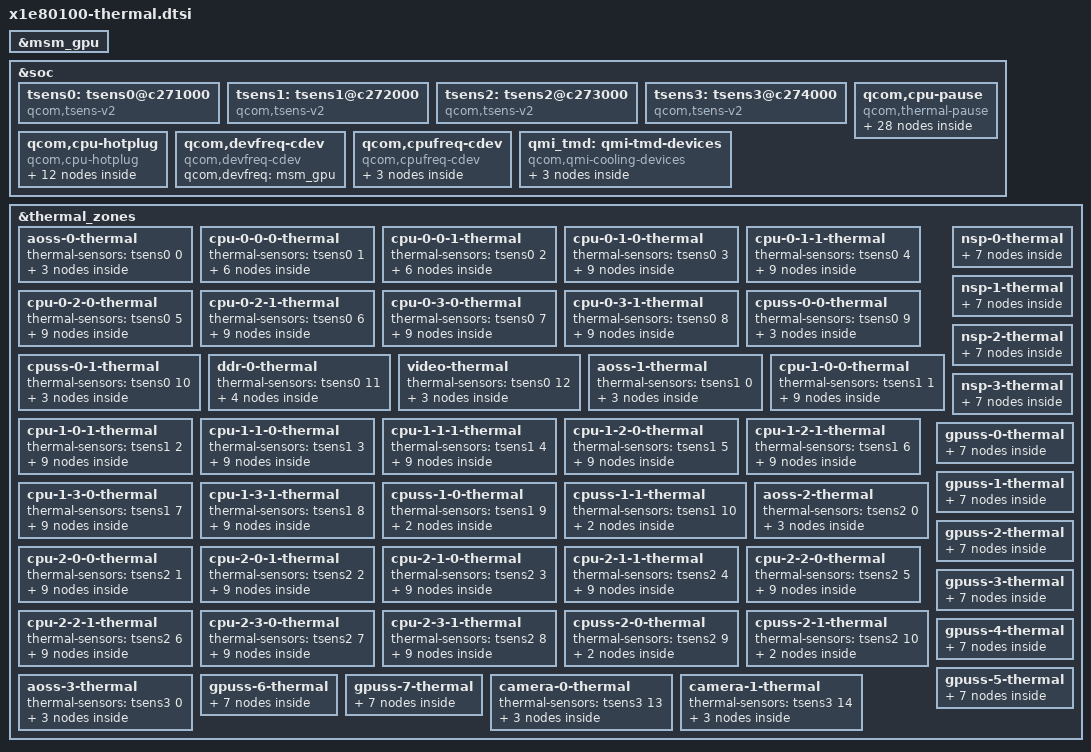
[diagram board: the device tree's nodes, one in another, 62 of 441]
// SPDX-License-Identifier: BSD-3-Clause
/*
 * Copyright (c) Qualcomm Technologies, Inc. and/or its subsidiaries.
 */

#include <dt-bindings/thermal/thermal_qti.h>

&msm_gpu {
	#cooling-cells = <2>;
};

&soc {
	tsens0: tsens0@c271000 {
		compatible = "qcom,tsens-v2";
		reg = <0x0 0xc271000 0x0 0x1ff>, /* TM */
				<0x0 0xc222000 0x0 0x1ff>; /* SROT */
		#qcom,sensors = <13>;
		interrupts = <GIC_SPI 506 IRQ_TYPE_LEVEL_HIGH>,
				<GIC_SPI 641 IRQ_TYPE_LEVEL_HIGH>;
		interrupt-names = "uplow","critical";
		#thermal-sensor-cells = <1>;
	};

	tsens1: tsens1@c272000 {
		compatible = "qcom,tsens-v2";
		reg = <0x0 0xc272000 0x0 0x1ff>, /* TM */
				<0x0 0xc223000 0x0 0x1ff>; /* SROT */
		#qcom,sensors = <11>;
		interrupts = <GIC_SPI 507 IRQ_TYPE_LEVEL_HIGH>,
				<GIC_SPI 642 IRQ_TYPE_LEVEL_HIGH>;
		interrupt-names = "uplow","critical";
		#thermal-sensor-cells = <1>;
	};

	tsens2: tsens2@c273000 {
		compatible = "qcom,tsens-v2";
		reg = <0x0 0xc273000 0x0 0x1ff>, /* TM */
				<0x0 0xc224000 0x0 0x1ff>; /* SROT */
		#qcom,sensors = <11>;
		interrupts = <GIC_SPI 508 IRQ_TYPE_LEVEL_HIGH>,
				<GIC_SPI 643 IRQ_TYPE_LEVEL_HIGH>;
		interrupt-names = "uplow","critical";
		#thermal-sensor-cells = <1>;
	};

	tsens3: tsens3@c274000 {
		compatible = "qcom,tsens-v2";
		reg = <0x0 0xc274000 0x0 0x1ff>, /* TM */
				<0x0 0xc225000 0x0 0x1ff>; /* SROT */
		#qcom,sensors = <15>;
		interrupts = <GIC_SPI 509 IRQ_TYPE_LEVEL_HIGH>,
				<GIC_SPI 770 IRQ_TYPE_LEVEL_HIGH>;
		interrupt-names = "uplow","critical";
		#thermal-sensor-cells = <1>;
	};

	qcom,cpu-pause {
		compatible = "qcom,thermal-pause";
		cpu0_pause: cpu0-pause {
			qcom,cpus = <&CPU0>;
			qcom,cdev-alias = "thermal-pause-1";
			#cooling-cells = <2>;
		};

		cpu1_pause: cpu1-pause {
			qcom,cpus = <&CPU1>;
			qcom,cdev-alias = "thermal-pause-2";
			#cooling-cells = <2>;
		};

		cpu2_pause: cpu2-pause {
			qcom,cpus = <&CPU2>;
			qcom,cdev-alias = "thermal-pause-4";
			#cooling-cells = <2>;
		};

		cpu3_pause: cpu3-pause {
			qcom,cpus = <&CPU3>;
			qcom,cdev-alias = "thermal-pause-8";
			#cooling-cells = <2>;
		};

		cpu4_pause: cpu4-pause {
			qcom,cpus = <&CPU4>;
			qcom,cdev-alias = "thermal-pause-10";
			#cooling-cells = <2>;
		};

		cpu5_pause: cpu5-pause {
			qcom,cpus = <&CPU5>;
			qcom,cdev-alias = "thermal-pause-20";
			#cooling-cells = <2>;
		};

		cpu6_pause: cpu6-pause {
			qcom,cpus = <&CPU6>;
			qcom,cdev-alias = "thermal-pause-40";
			#cooling-cells = <2>;
		};

		cpu7_pause: cpu7-pause {
			qcom,cpus = <&CPU7>;
			qcom,cdev-alias = "thermal-pause-80";
			#cooling-cells = <2>;
		};

		cpu8_pause: cpu8-pause {
			qcom,cpus = <&CPU8>;
			qcom,cdev-alias = "thermal-pause-100";
			#cooling-cells = <2>;
		};

		cpu9_pause: cpu9-pause {
			qcom,cpus = <&CPU9>;
			qcom,cdev-alias = "thermal-pause-200";
			#cooling-cells = <2>;
		};

		cpu10_pause: cpu10-pause {
			qcom,cpus = <&CPU10>;
			qcom,cdev-alias = "thermal-pause-400";
			#cooling-cells = <2>;
		};

		cpu11_pause: cpu11-pause {
			qcom,cpus = <&CPU11>;
			qcom,cdev-alias = "thermal-pause-800";
			#cooling-cells = <2>;
		};

		APC0_MX_CX_PAUSE: apc0-mx-cx-pause {
			qcom,cpus = <&CPU1 &CPU2 &CPU3>;
			qcom,cdev-alias = "thermal-pause-E";
			#cooling-cells = <2>;
		};

		APC1_MX_CX_PAUSE: apc1-mx-cx-pause {
			qcom,cpus = <&CPU4 &CPU5 &CPU6 &CPU7>;
			qcom,cdev-alias = "thermal-pause-F0";
			#cooling-cells = <2>;
		};

		APC2_MX_CX_PAUSE: apc2-mx-cx-pause {
			qcom,cpus = <&CPU8 &CPU9 &CPU10 &CPU11>;
			qcom,cdev-alias = "thermal-pause-F00";
			#cooling-cells = <2>;
		};

		APC1_APC2_MX_CX_PAUSE: apc1-apc2-mx-cx-pause {
			qcom,cpus = <&CPU4 &CPU5 &CPU6 &CPU7 &CPU8 &CPU9 &CPU10 &CPU11>;
			qcom,cdev-alias = "thermal-pause-FF0";
			#cooling-cells = <2>;
		};

		/* Thermal-engine cooling devices */
		pause-cpu0 {
			qcom,cpus = <&CPU0>;
			qcom,cdev-alias = "pause-cpu0";
		};

		pause-cpu1 {
			qcom,cpus = <&CPU1>;
			qcom,cdev-alias = "pause-cpu1";
		};

		pause-cpu2 {
			qcom,cpus = <&CPU2>;
			qcom,cdev-alias = "pause-cpu2";
		};

		pause-cpu3 {
			qcom,cpus = <&CPU3>;
			qcom,cdev-alias = "pause-cpu3";
		};

		pause-cpu4 {
			qcom,cpus = <&CPU4>;
			qcom,cdev-alias = "pause-cpu4";
		};

		pause-cpu5 {
			qcom,cpus = <&CPU5>;
			qcom,cdev-alias = "pause-cpu5";
		};

		pause-cpu6 {
			qcom,cpus = <&CPU6>;
			qcom,cdev-alias = "pause-cpu6";
		};

		pause-cpu7 {
			qcom,cpus = <&CPU7>;
			qcom,cdev-alias = "pause-cpu7";
		};

		pause-cpu8 {
			qcom,cpus = <&CPU8>;
			qcom,cdev-alias = "pause-cpu8";
		};

		pause-cpu9 {
			qcom,cpus = <&CPU9>;
			qcom,cdev-alias = "pause-cpu9";
		};

		pause-cpu10 {
			qcom,cpus = <&CPU10>;
			qcom,cdev-alias = "pause-cpu10";
		};

		pause-cpu11 {
			qcom,cpus = <&CPU11>;
			qcom,cdev-alias = "pause-cpu11";
		};
	};

	qcom,cpu-hotplug {
		compatible = "qcom,cpu-hotplug";
		cpu0_hotplug: cpu0-hotplug {
			qcom,cpu = <&CPU0>;
			qcom,cdev-alias = "cpu-hotplug0";
			#cooling-cells = <2>;
		};

		cpu1_hotplug: cpu1-hotplug {
			qcom,cpu = <&CPU1>;
			qcom,cdev-alias = "cpu-hotplug1";
			#cooling-cells = <2>;
		};

		cpu2_hotplug: cpu2-hotplug {
			qcom,cpu = <&CPU2>;
			qcom,cdev-alias = "cpu-hotplug2";
			#cooling-cells = <2>;
		};

		cpu3_hotplug: cpu3-hotplug {
			qcom,cpu = <&CPU3>;
			qcom,cdev-alias = "cpu-hotplug3";
			#cooling-cells = <2>;
		};

		cpu4_hotplug: cpu4-hotplug {
			qcom,cpu = <&CPU4>;
			qcom,cdev-alias = "cpu-hotplug4";
			#cooling-cells = <2>;
		};

		cpu5_hotplug: cpu5-hotplug {
			qcom,cpu = <&CPU5>;
			qcom,cdev-alias = "cpu-hotplug5";
			#cooling-cells = <2>;
		};

		cpu6_hotplug: cpu6-hotplug {
			qcom,cpu = <&CPU6>;
			qcom,cdev-alias = "cpu-hotplug6";
			#cooling-cells = <2>;
		};

		cpu7_hotplug: cpu7-hotplug {
			qcom,cpu = <&CPU7>;
			qcom,cdev-alias = "cpu-hotplug7";
			#cooling-cells = <2>;
		};

		cpu8_hotplug: cpu8-hotplug {
			qcom,cpu = <&CPU8>;
			qcom,cdev-alias = "cpu-hotplug8";
			#cooling-cells = <2>;
		};

		cpu9_hotplug: cpu9-hotplug {
			qcom,cpu = <&CPU9>;
			qcom,cdev-alias = "cpu-hotplug9";
			#cooling-cells = <2>;
		};

		cpu10_hotplug: cpu10-hotplug {
			qcom,cpu = <&CPU10>;
			qcom,cdev-alias = "cpu-hotplug10";
			#cooling-cells = <2>;
		};

		cpu11_hotplug: cpu11-hotplug {
			qcom,cpu = <&CPU11>;
			qcom,cdev-alias = "cpu-hotplug11";
			#cooling-cells = <2>;
		};
	};

	qcom,devfreq-cdev {
		compatible = "qcom,devfreq-cdev";
		qcom,devfreq = <&msm_gpu>;
	};

	qcom,cpufreq-cdev {
		compatible = "qcom,cpufreq-cdev";
		cpu-cluster0 {
			qcom,cpus = <&CPU0 &CPU1 &CPU2 &CPU3>;
		};

		cpu-cluster1 {
			qcom,cpus = <&CPU4 &CPU5 &CPU6 &CPU7>;
		};

		cpu-cluster2 {
			qcom,cpus = <&CPU8 &CPU9 &CPU10 &CPU11>;
		};
	};

	qmi_tmd: qmi-tmd-devices {
		compatible = "qcom,qmi-cooling-devices";
		cdsp {
			qcom,instance-id = <QMI_CDSP_INST_ID>;
			cdsp_sw: cdsp {
				qcom,qmi-dev-name = "cdsp_sw";
				#cooling-cells = <2>;
			};

			cdsp_hw: cdsp_hw {
				qcom,qmi-dev-name = "cdsp_hw";
				#cooling-cells = <2>;
			};
		};
	};
};

&thermal_zones {
	aoss-0-thermal {
		thermal-sensors = <&tsens0 0>;
		trips {
			thermal-engine-config {
				temperature = <135000>;
				hysteresis = <5000>;
				type = "passive";
			};

			reset-mon-cfg {
				temperature = <115000>;
				hysteresis = <0>;
				type = "hot";
			};
		};
	};

	cpu-0-0-0-thermal {
		thermal-sensors = <&tsens0 1>;
		trips {
			thermal-engine-config {
				temperature = <135000>;
				hysteresis = <5000>;
				type = "passive";
			};

			thermal-hal-config {
				temperature = <95000>;
				hysteresis = <5000>;
				type = "passive";
			};

			cpu0_emerg0: cpu0-emerg0-cfg {
				temperature = <108000>;
				hysteresis = <8000>;
				type = "passive";
			};

			cpu0_emerg0_1: cpu0-emerg0-1-cfg {
				temperature = <110000>;
				hysteresis = <10000>;
				type = "passive";
			};

			reset-mon-cfg {
				temperature = <115000>;
				hysteresis = <0>;
				type = "hot";
			};
		};
	};

	cpu-0-0-1-thermal {
		thermal-sensors = <&tsens0 2>;
		trips {
			thermal-engine-config {
				temperature = <135000>;
				hysteresis = <5000>;
				type = "passive";
			};

			thermal-hal-config {
				temperature = <95000>;
				hysteresis = <5000>;
				type = "passive";
			};

			cpu0_emerg1: cpu0-emerg1-cfg {
				temperature = <108000>;
				hysteresis = <8000>;
				type = "passive";
			};

			cpu0_emerg1_1: cpu0-emerg1-1-cfg {
				temperature = <110000>;
				hysteresis = <10000>;
				type = "passive";
			};

			reset-mon-cfg {
				temperature = <115000>;
				hysteresis = <0>;
				type = "hot";
			};
		};
	};

	cpu-0-1-0-thermal {
		thermal-sensors = <&tsens0 3>;
		trips {
			thermal-engine-config {
				temperature = <135000>;
				hysteresis = <5000>;
				type = "passive";
			};

			thermal-hal-config {
				temperature = <95000>;
				hysteresis = <5000>;
				type = "passive";
			};

			cpu1_emerg0: cpu1-emerg0-cfg {
				temperature = <108000>;
				hysteresis = <8000>;
				type = "passive";
			};

			cpu1_emerg0_1: cpu1-emerg0-1-cfg {
				temperature = <110000>;
				hysteresis = <10000>;
				type = "passive";
			};

			reset-mon-cfg {
				temperature = <115000>;
				hysteresis = <0>;
				type = "hot";
			};
		};

		cooling-maps {
			cpu010_cdev {
				trip = <&cpu1_emerg0>;
				cooling-device = <&cpu1_pause 1 1>;
			};

			cpu010_cdev1 {
				trip = <&cpu1_emerg0_1>;
				cooling-device = <&cpu1_hotplug 1 1>;
			};
		};
	};

	cpu-0-1-1-thermal {
		thermal-sensors = <&tsens0 4>;
		trips {
			thermal-engine-config {
				temperature = <135000>;
				hysteresis = <5000>;
				type = "passive";
			};

			thermal-hal-config {
				temperature = <95000>;
				hysteresis = <5000>;
				type = "passive";
			};

			cpu1_emerg1: cpu1-emerg1-cfg {
				temperature = <108000>;
				hysteresis = <8000>;
				type = "passive";
			};

			cpu1_emerg1_1: cpu1-emerg1-1-cfg {
				temperature = <110000>;
				hysteresis = <10000>;
				type = "passive";
			};

			reset-mon-cfg {
				temperature = <115000>;
				hysteresis = <0>;
				type = "hot";
			};
		};

		cooling-maps {
			cpu011_cdev {
				trip = <&cpu1_emerg1>;
				cooling-device = <&cpu1_pause 1 1>;
			};

			cpu011_cdev1 {
				trip = <&cpu1_emerg1_1>;
				cooling-device = <&cpu1_hotplug 1 1>;
			};
		};
	};

	cpu-0-2-0-thermal {
		thermal-sensors = <&tsens0 5>;
		trips {
			thermal-engine-config {
				temperature = <135000>;
				hysteresis = <5000>;
				type = "passive";
			};

			thermal-hal-config {
				temperature = <95000>;
				hysteresis = <5000>;
				type = "passive";
			};

			cpu2_emerg0: cpu2-emerg0-cfg {
				temperature = <108000>;
				hysteresis = <8000>;
				type = "passive";
			};

			cpu2_emerg0_1: cpu2-emerg0-1-cfg {
				temperature = <110000>;
				hysteresis = <10000>;
				type = "passive";
			};

			reset-mon-cfg {
				temperature = <115000>;
				hysteresis = <0>;
				type = "hot";
			};
		};

		cooling-maps {
			cpu020_cdev {
				trip = <&cpu2_emerg0>;
				cooling-device = <&cpu2_pause 1 1>;
			};

			cpu020_cdev1 {
				trip = <&cpu2_emerg0_1>;
				cooling-device = <&cpu2_hotplug 1 1>;
			};
		};
	};

	cpu-0-2-1-thermal {
		thermal-sensors = <&tsens0 6>;
		trips {
			thermal-engine-config {
				temperature = <135000>;
				hysteresis = <5000>;
				type = "passive";
			};

			thermal-hal-config {
				temperature = <95000>;
				hysteresis = <5000>;
				type = "passive";
			};

			cpu2_emerg1: cpu2-emerg1-cfg {
				temperature = <108000>;
				hysteresis = <8000>;
				type = "passive";
			};

			cpu2_emerg1_1: cpu2-emerg1-1-cfg {
				temperature = <110000>;
				hysteresis = <10000>;
				type = "passive";
			};

			reset-mon-cfg {
				temperature = <115000>;
				hysteresis = <0>;
				type = "hot";
			};
		};

		cooling-maps {
			cpu021_cdev {
				trip = <&cpu2_emerg1>;
				cooling-device = <&cpu2_pause 1 1>;
			};

			cpu021_cdev1 {
				trip = <&cpu2_emerg1_1>;
				cooling-device = <&cpu2_hotplug 1 1>;
			};
		};
	};

	cpu-0-3-0-thermal {
		thermal-sensors = <&tsens0 7>;
		trips {
			thermal-engine-config {
				temperature = <135000>;
				hysteresis = <5000>;
				type = "passive";
			};

			thermal-hal-config {
				temperature = <95000>;
				hysteresis = <5000>;
				type = "passive";
			};

			cpu3_emerg0: cpu3-emerg0-cfg {
				temperature = <108000>;
				hysteresis = <8000>;
				type = "passive";
			};

			cpu3_emerg0_1: cpu3-emerg0-1-cfg {
				temperature = <110000>;
				hysteresis = <10000>;
				type = "passive";
			};

			reset-mon-cfg {
				temperature = <115000>;
				hysteresis = <0>;
				type = "hot";
			};
		};

		cooling-maps {
			cpu030_cdev {
				trip = <&cpu3_emerg0>;
				cooling-device = <&cpu3_pause 1 1>;
			};

			cpu030_cdev1 {
				trip = <&cpu3_emerg0_1>;
				cooling-device = <&cpu3_hotplug 1 1>;
			};
		};
	};

	cpu-0-3-1-thermal {
		thermal-sensors = <&tsens0 8>;
		trips {
			thermal-engine-config {
				temperature = <135000>;
				hysteresis = <5000>;
				type = "passive";
			};

			thermal-hal-config {
				temperature = <95000>;
				hysteresis = <5000>;
				type = "passive";
			};

			cpu3_emerg1: cpu3-emerg1-cfg {
				temperature = <108000>;
				hysteresis = <8000>;
				type = "passive";
			};

			cpu3_emerg1_1: cpu3-emerg1-1-cfg {
				temperature = <110000>;
				hysteresis = <10000>;
				type = "passive";
			};

			reset-mon-cfg {
				temperature = <115000>;
				hysteresis = <0>;
				type = "hot";
			};
		};

		cooling-maps {
			cpu031_cdev {
				trip = <&cpu3_emerg1>;
				cooling-device = <&cpu3_pause 1 1>;
			};

			cpu031_cdev1 {
				trip = <&cpu3_emerg1_1>;
				cooling-device = <&cpu3_hotplug 1 1>;
			};
		};
	};

	cpuss-0-0-thermal {
		thermal-sensors = <&tsens0 9>;
		trips {
			thermal-engine-config {
				temperature = <135000>;
				hysteresis = <5000>;
				type = "passive";
			};

			reset-mon-cfg {
				temperature = <115000>;
				hysteresis = <0>;
				type = "hot";
			};
		};
	};

	cpuss-0-1-thermal {
		thermal-sensors = <&tsens0 10>;
		trips {
			thermal-engine-config {
				temperature = <135000>;
				hysteresis = <5000>;
				type = "passive";
			};

			reset-mon-cfg {
				temperature = <115000>;
				hysteresis = <0>;
				type = "hot";
			};
		};
	};

	ddr-0-thermal {
		thermal-sensors = <&tsens0 11>;
		trips {
			thermal-engine-config {
				temperature = <135000>;
				hysteresis = <5000>;
				type = "passive";
			};

			ddr_config0: ddr0-config {
				temperature = <90000>;
				hysteresis = <5000>;
				type = "passive";
			};

			reset-mon-cfg {
				temperature = <115000>;
				hysteresis = <0>;
				type = "hot";
			};
		};
	};

	video-thermal {
		thermal-sensors = <&tsens0 12>;
		trips {
			thermal-engine-config {
				temperature = <135000>;
				hysteresis = <5000>;
				type = "passive";
			};

			reset-mon-cfg {
				temperature = <115000>;
				hysteresis = <0>;
				type = "hot";
			};
		};
	};

	aoss-1-thermal {
		thermal-sensors = <&tsens1 0>;
		trips {
			thermal-engine-config {
				temperature = <135000>;
				hysteresis = <5000>;
				type = "passive";
			};

			reset-mon-cfg {
				temperature = <115000>;
				hysteresis = <0>;
				type = "hot";
			};
		};
	};

	cpu-1-0-0-thermal {
		thermal-sensors = <&tsens1 1>;
		trips {
			thermal-engine-config {
				temperature = <135000>;
				hysteresis = <5000>;
				type = "passive";
			};

			thermal-hal-config {
				temperature = <95000>;
				hysteresis = <5000>;
				type = "passive";
			};

			cpu4_emerg0: cpu4-emerg0-cfg {
				temperature = <108000>;
				hysteresis = <8000>;
				type = "passive";
			};

			cpu4_emerg0_1: cpu4-emerg0-1-cfg {
				temperature = <110000>;
				hysteresis = <10000>;
				type = "passive";
			};

			reset-mon-cfg {
				temperature = <115000>;
				hysteresis = <0>;
				type = "hot";
			};
		};

		cooling-maps {
			cpu100_cdev {
				trip = <&cpu4_emerg0>;
				cooling-device = <&cpu4_pause 1 1>;
			};

			cpu100_cdev1 {
				trip = <&cpu4_emerg0_1>;
				cooling-device = <&cpu4_hotplug 1 1>;
			};
		};
	};

	cpu-1-0-1-thermal {
		thermal-sensors = <&tsens1 2>;
		trips {
			thermal-engine-config {
				temperature = <135000>;
				hysteresis = <5000>;
				type = "passive";
			};

			thermal-hal-config {
				temperature = <95000>;
				hysteresis = <5000>;
				type = "passive";
			};

			cpu4_emerg1: cpu4-emerg1-cfg {
				temperature = <108000>;
				hysteresis = <8000>;
				type = "passive";
			};

			cpu4_emerg1_1: cpu4-emerg1-1-cfg {
				temperature = <110000>;
				hysteresis = <10000>;
				type = "passive";
			};

			reset-mon-cfg {
				temperature = <115000>;
				hysteresis = <0>;
				type = "hot";
			};
		};

		cooling-maps {
			cpu101_cdev {
				trip = <&cpu4_emerg1>;
				cooling-device = <&cpu4_pause 1 1>;
			};

			cpu101_cdev1 {
				trip = <&cpu4_emerg1_1>;
				cooling-device = <&cpu4_hotplug 1 1>;
			};
		};
	};

	cpu-1-1-0-thermal {
		thermal-sensors = <&tsens1 3>;
		trips {
			thermal-engine-config {
				temperature = <135000>;
				hysteresis = <5000>;
				type = "passive";
			};

			thermal-hal-config {
				temperature = <95000>;
				hysteresis = <5000>;
				type = "passive";
			};

			cpu5_emerg0: cpu5-emerg0-cfg {
				temperature = <108000>;
				hysteresis = <8000>;
				type = "passive";
			};

			cpu5_emerg0_1: cpu5-emerg0-1-cfg {
				temperature = <110000>;
				hysteresis = <10000>;
				type = "passive";
			};

			reset-mon-cfg {
				temperature = <115000>;
				hysteresis = <0>;
				type = "hot";
			};
		};

		cooling-maps {
			cpu110_cdev {
				trip = <&cpu5_emerg0>;
				cooling-device = <&cpu5_pause 1 1>;
			};

			cpu110_cdev1 {
				trip = <&cpu5_emerg0_1>;
				cooling-device = <&cpu5_hotplug 1 1>;
			};
		};
	};

	cpu-1-1-1-thermal {
		thermal-sensors = <&tsens1 4>;
		trips {
			thermal-engine-config {
				temperature = <135000>;
				hysteresis = <5000>;
				type = "passive";
			};

			thermal-hal-config {
				temperature = <95000>;
				hysteresis = <5000>;
				type = "passive";
			};

			cpu5_emerg1: cpu5-emerg1-cfg {
				temperature = <108000>;
				hysteresis = <8000>;
				type = "passive";
			};

			cpu5_emerg1_1: cpu5-emerg1-1-cfg {
				temperature = <110000>;
				hysteresis = <10000>;
				type = "passive";
			};

			reset-mon-cfg {
				temperature = <115000>;
				hysteresis = <0>;
				type = "hot";
			};
		};

		cooling-maps {
			cpu111_cdev {
				trip = <&cpu5_emerg1>;
				cooling-device = <&cpu5_pause 1 1>;
			};

			cpu111_cdev1 {
				trip = <&cpu5_emerg1_1>;
				cooling-device = <&cpu5_hotplug 1 1>;
			};
		};
	};

	cpu-1-2-0-thermal {
		thermal-sensors = <&tsens1 5>;
		trips {
			thermal-engine-config {
				temperature = <135000>;
				hysteresis = <5000>;
				type = "passive";
			};

			thermal-hal-config {
				temperature = <95000>;
				hysteresis = <5000>;
				type = "passive";
			};

			cpu6_emerg0: cpu6-emerg0-cfg {
				temperature = <108000>;
				hysteresis = <8000>;
				type = "passive";
			};

			cpu6_emerg0_1: cpu6-emerg0-1-cfg {
				temperature = <110000>;
				hysteresis = <10000>;
				type = "passive";
			};

			reset-mon-cfg {
				temperature = <115000>;
				hysteresis = <0>;
				type = "hot";
			};
		};

		cooling-maps {
			cpu120_cdev {
				trip = <&cpu6_emerg0>;
				cooling-device = <&cpu6_pause 1 1>;
			};

			cpu120_cdev1 {
				trip = <&cpu6_emerg0_1>;
				cooling-device = <&cpu6_hotplug 1 1>;
			};
		};
	};

	cpu-1-2-1-thermal {
		thermal-sensors = <&tsens1 6>;
		trips {
			thermal-engine-config {
				temperature = <135000>;
				hysteresis = <5000>;
				type = "passive";
			};

			thermal-hal-config {
				temperature = <95000>;
				hysteresis = <5000>;
				type = "passive";
			};

			cpu6_emerg1: cpu6-emerg1-cfg {
				temperature = <108000>;
				hysteresis = <8000>;
				type = "passive";
			};

			cpu6_emerg1_1: cpu6-emerg1-1-cfg {
				temperature = <110000>;
				hysteresis = <10000>;
				type = "passive";
			};

			reset-mon-cfg {
				temperature = <115000>;
				hysteresis = <0>;
				type = "hot";
			};
		};

		cooling-maps {
			cpu121_cdev {
				trip = <&cpu6_emerg1>;
				cooling-device = <&cpu6_pause 1 1>;
			};

			cpu121_cdev1 {
				trip = <&cpu6_emerg1_1>;
				cooling-device = <&cpu6_hotplug 1 1>;
			};
		};
	};

	cpu-1-3-0-thermal {
		thermal-sensors = <&tsens1 7>;
		trips {
			thermal-engine-config {
				temperature = <135000>;
				hysteresis = <5000>;
				type = "passive";
			};

			thermal-hal-config {
				temperature = <95000>;
				hysteresis = <5000>;
				type = "passive";
			};

			cpu7_emerg0: cpu7-emerg0-cfg {
				temperature = <108000>;
				hysteresis = <8000>;
				type = "passive";
			};

			cpu7_emerg0_1: cpu7-emerg0-1-cfg {
				temperature = <110000>;
				hysteresis = <10000>;
				type = "passive";
			};

			reset-mon-cfg {
				temperature = <115000>;
				hysteresis = <0>;
				type = "hot";
			};
		};

		cooling-maps {
			cpu130_cdev {
				trip = <&cpu7_emerg0>;
				cooling-device = <&cpu7_pause 1 1>;
			};

			cpu130_cdev1 {
				trip = <&cpu7_emerg0_1>;
				cooling-device = <&cpu7_hotplug 1 1>;
			};
		};
	};

	cpu-1-3-1-thermal {
		thermal-sensors = <&tsens1 8>;
		trips {
			thermal-engine-config {
				temperature = <135000>;
				hysteresis = <5000>;
				type = "passive";
			};

			thermal-hal-config {
				temperature = <95000>;
				hysteresis = <5000>;
				type = "passive";
			};

			cpu7_emerg1: cpu7-emerg1-cfg {
				temperature = <108000>;
				hysteresis = <8000>;
				type = "passive";
			};

			cpu7_emerg1_1: cpu7-emerg1-1-cfg {
				temperature = <110000>;
				hysteresis = <10000>;
				type = "passive";
			};

			reset-mon-cfg {
				temperature = <115000>;
				hysteresis = <0>;
				type = "hot";
			};
		};

		cooling-maps {
			cpu131_cdev {
				trip = <&cpu7_emerg1>;
				cooling-device = <&cpu7_pause 1 1>;
			};

			cpu131_cdev1 {
				trip = <&cpu7_emerg1_1>;
				cooling-device = <&cpu7_hotplug 1 1>;
			};
		};
	};

	cpuss-1-0-thermal {
		thermal-sensors = <&tsens1 9>;
		trips {
			trip-point0 {
				temperature = <125000>;
				hysteresis = <5000>;
				type = "passive";
			};
		};
	};

	cpuss-1-1-thermal {
		thermal-sensors = <&tsens1 10>;
		trips {
			trip-point0 {
				temperature = <125000>;
				hysteresis = <5000>;
				type = "passive";
			};
		};
	};

	aoss-2-thermal {
		thermal-sensors = <&tsens2 0>;
		trips {
			thermal-engine-config {
				temperature = <135000>;
				hysteresis = <5000>;
				type = "passive";
			};

			reset-mon-cfg {
				temperature = <115000>;
				hysteresis = <0>;
				type = "hot";
			};
		};
	};

	cpu-2-0-0-thermal {
		thermal-sensors = <&tsens2 1>;
		trips {
			thermal-engine-config {
				temperature = <135000>;
				hysteresis = <5000>;
				type = "passive";
			};

			thermal-hal-config {
				temperature = <95000>;
				hysteresis = <5000>;
				type = "passive";
			};

			cpu8_emerg0: cpu8-emerg0-cfg {
				temperature = <108000>;
				hysteresis = <8000>;
				type = "passive";
			};

			cpu8_emerg0_1: cpu8-emerg0-1-cfg {
				temperature = <110000>;
				hysteresis = <10000>;
				type = "passive";
			};

			reset-mon-cfg {
				temperature = <115000>;
				hysteresis = <0>;
				type = "hot";
			};
		};

		cooling-maps {
			cpu200_cdev {
				trip = <&cpu8_emerg0>;
				cooling-device = <&cpu8_pause 1 1>;
			};

			cpu200_cdev1 {
				trip = <&cpu8_emerg0_1>;
				cooling-device = <&cpu8_hotplug 1 1>;
			};
		};
	};

	cpu-2-0-1-thermal {
		thermal-sensors = <&tsens2 2>;
		trips {
			thermal-engine-config {
				temperature = <135000>;
				hysteresis = <5000>;
				type = "passive";
			};

			thermal-hal-config {
				temperature = <95000>;
				hysteresis = <5000>;
				type = "passive";
			};

			cpu8_emerg1: cpu8-emerg1-cfg {
				temperature = <108000>;
				hysteresis = <8000>;
				type = "passive";
			};

			cpu8_emerg1_1: cpu8-emerg1-1-cfg {
				temperature = <110000>;
				hysteresis = <10000>;
				type = "passive";
			};

			reset-mon-cfg {
				temperature = <115000>;
				hysteresis = <0>;
				type = "hot";
			};
		};

		cooling-maps {
			cpu201_cdev {
				trip = <&cpu8_emerg1>;
				cooling-device = <&cpu8_pause 1 1>;
			};

			cpu201_cdev1 {
				trip = <&cpu8_emerg1_1>;
				cooling-device = <&cpu8_hotplug 1 1>;
			};
		};
	};

	cpu-2-1-0-thermal {
		thermal-sensors = <&tsens2 3>;
		trips {
			thermal-engine-config {
				temperature = <135000>;
				hysteresis = <5000>;
				type = "passive";
			};

			thermal-hal-config {
				temperature = <95000>;
				hysteresis = <5000>;
				type = "passive";
			};

			cpu9_emerg0: cpu9-emerg0-cfg {
				temperature = <108000>;
				hysteresis = <8000>;
				type = "passive";
			};

			cpu9_emerg0_1: cpu9-emerg0-1-cfg {
				temperature = <110000>;
				hysteresis = <10000>;
				type = "passive";
			};

			reset-mon-cfg {
				temperature = <115000>;
				hysteresis = <0>;
				type = "hot";
			};
		};

		cooling-maps {
			cpu210_cdev {
				trip = <&cpu9_emerg0>;
				cooling-device = <&cpu9_pause 1 1>;
			};

			cpu210_cdev1 {
				trip = <&cpu9_emerg0_1>;
				cooling-device = <&cpu9_hotplug 1 1>;
			};
		};
	};

	cpu-2-1-1-thermal {
		thermal-sensors = <&tsens2 4>;
		trips {
			thermal-engine-config {
				temperature = <135000>;
				hysteresis = <5000>;
				type = "passive";
			};

			thermal-hal-config {
				temperature = <95000>;
				hysteresis = <5000>;
				type = "passive";
			};

			cpu9_emerg1: cpu9-emerg1-cfg {
				temperature = <108000>;
				hysteresis = <8000>;
				type = "passive";
			};

			cpu9_emerg1_1: cpu9-emerg1-1-cfg {
				temperature = <110000>;
				hysteresis = <10000>;
				type = "passive";
			};

			reset-mon-cfg {
				temperature = <115000>;
				hysteresis = <0>;
				type = "hot";
			};
		};

		cooling-maps {
			cpu211_cdev {
				trip = <&cpu9_emerg1>;
				cooling-device = <&cpu9_pause 1 1>;
			};

			cpu211_cdev1 {
				trip = <&cpu9_emerg1_1>;
				cooling-device = <&cpu9_hotplug 1 1>;
			};
		};
	};

	cpu-2-2-0-thermal {
		thermal-sensors = <&tsens2 5>;
		trips {
			thermal-engine-config {
				temperature = <135000>;
				hysteresis = <5000>;
				type = "passive";
			};

			thermal-hal-config {
				temperature = <95000>;
				hysteresis = <5000>;
				type = "passive";
			};

			cpu10_emerg0: cpu10-emerg0-cfg {
				temperature = <108000>;
				hysteresis = <8000>;
				type = "passive";
			};

			cpu10_emerg0_1: cpu10-emerg0-1-cfg {
				temperature = <110000>;
				hysteresis = <10000>;
				type = "passive";
			};

			reset-mon-cfg {
				temperature = <115000>;
				hysteresis = <0>;
				type = "hot";
			};
		};

		cooling-maps {
			cpu220_cdev {
				trip = <&cpu10_emerg0>;
				cooling-device = <&cpu10_pause 1 1>;
			};

			cpu220_cdev1 {
				trip = <&cpu10_emerg0_1>;
				cooling-device = <&cpu10_hotplug 1 1>;
			};
		};
	};

	cpu-2-2-1-thermal {
		thermal-sensors = <&tsens2 6>;
		trips {
			thermal-engine-config {
				temperature = <135000>;
				hysteresis = <5000>;
				type = "passive";
			};

			thermal-hal-config {
				temperature = <95000>;
				hysteresis = <5000>;
				type = "passive";
			};

			cpu10_emerg1: cpu10-emerg1-cfg {
				temperature = <108000>;
				hysteresis = <8000>;
				type = "passive";
			};

			cpu10_emerg1_1: cpu10-emerg1-1-cfg {
				temperature = <110000>;
				hysteresis = <10000>;
				type = "passive";
			};

			reset-mon-cfg {
				temperature = <115000>;
				hysteresis = <0>;
				type = "hot";
			};
		};

		cooling-maps {
			cpu221_cdev {
				trip = <&cpu10_emerg1>;
				cooling-device = <&cpu10_pause 1 1>;
			};

			cpu221_cdev1 {
				trip = <&cpu10_emerg1_1>;
				cooling-device = <&cpu10_hotplug 1 1>;
			};
		};
	};

	cpu-2-3-0-thermal {
		thermal-sensors = <&tsens2 7>;
		trips {
			thermal-engine-config {
				temperature = <135000>;
				hysteresis = <5000>;
				type = "passive";
			};

			thermal-hal-config {
				temperature = <95000>;
				hysteresis = <5000>;
				type = "passive";
			};

			cpu11_emerg0: cpu11-emerg0-cfg {
				temperature = <108000>;
				hysteresis = <8000>;
				type = "passive";
			};

			cpu11_emerg0_1: cpu11-emerg0-1-cfg {
				temperature = <110000>;
				hysteresis = <10000>;
				type = "passive";
			};

			reset-mon-cfg {
				temperature = <115000>;
				hysteresis = <0>;
				type = "hot";
			};
		};

		cooling-maps {
			cpu230_cdev {
				trip = <&cpu11_emerg0>;
				cooling-device = <&cpu11_pause 1 1>;
			};

			cpu230_cdev1 {
				trip = <&cpu11_emerg0_1>;
				cooling-device = <&cpu11_hotplug 1 1>;
			};
		};
	};

	cpu-2-3-1-thermal {
		thermal-sensors = <&tsens2 8>;
		trips {
			thermal-engine-config {
				temperature = <135000>;
				hysteresis = <5000>;
				type = "passive";
			};

			thermal-hal-config {
				temperature = <95000>;
				hysteresis = <5000>;
				type = "passive";
			};

			cpu11_emerg1: cpu11-emerg1-cfg {
				temperature = <108000>;
				hysteresis = <8000>;
				type = "passive";
			};

			cpu11_emerg1_1: cpu11-emerg1-1-cfg {
				temperature = <110000>;
				hysteresis = <10000>;
				type = "passive";
			};

			reset-mon-cfg {
				temperature = <115000>;
				hysteresis = <0>;
				type = "hot";
			};
		};

		cooling-maps {
			cpu231_cdev {
				trip = <&cpu11_emerg1>;
				cooling-device = <&cpu11_pause 1 1>;
			};

			cpu231_cdev1 {
				trip = <&cpu11_emerg1_1>;
				cooling-device = <&cpu11_hotplug 1 1>;
			};
		};
	};

	cpuss-2-0-thermal {
		thermal-sensors = <&tsens2 9>;
		trips {
			trip-point0 {
				temperature = <125000>;
				hysteresis = <5000>;
				type = "passive";
			};
		};
	};

	cpuss-2-1-thermal {
		thermal-sensors = <&tsens2 10>;
		trips {
			trip-point0 {
				temperature = <125000>;
				hysteresis = <5000>;
				type = "passive";
			};
		};
	};

	aoss-3-thermal {
		thermal-sensors = <&tsens3 0>;
		trips {
			thermal-engine-config {
				temperature = <135000>;
				hysteresis = <5000>;
				type = "passive";
			};

			reset-mon-cfg {
				temperature = <115000>;
				hysteresis = <0>;
				type = "hot";
			};
		};
	};

	nsp-0-thermal {
		polling-delay-passive = <10>;
		thermal-sensors = <&tsens3 1>;
		trips {
			thermal-engine-config {
				temperature = <135000>;
				hysteresis = <5000>;
				type = "passive";
			};

			thermal-hal-config {
				temperature = <95000>;
				hysteresis = <5000>;
				type = "passive";
			};

			nsp_0_trip: nsp-0-trip {
				temperature = <95000>;
				hysteresis = <5000>;
				type = "passive";
			};

			reset-mon-cfg {
				temperature = <115000>;
				hysteresis = <0>;
				type = "hot";
			};
		};

		cooling-maps {
			cdsp_cdev {
				trip = <&nsp_0_trip>;
				cooling-device = <&cdsp_sw 0 THERMAL_NO_LIMIT>;
			};
		};
	};

	nsp-1-thermal {
		polling-delay-passive = <10>;
		thermal-sensors = <&tsens3 2>;
		trips {
			thermal-engine-config {
				temperature = <135000>;
				hysteresis = <5000>;
				type = "passive";
			};

			thermal-hal-config {
				temperature = <95000>;
				hysteresis = <5000>;
				type = "passive";
			};

			nsp_1_trip: nsp-1-trip {
				temperature = <95000>;
				hysteresis = <5000>;
				type = "passive";
			};

			reset-mon-cfg {
				temperature = <115000>;
				hysteresis = <0>;
				type = "hot";
			};
		};

		cooling-maps {
			cdsp_cdev {
				trip = <&nsp_1_trip>;
				cooling-device = <&cdsp_sw 0 THERMAL_NO_LIMIT>;
			};
		};
	};

	nsp-2-thermal {
		polling-delay-passive = <10>;
		thermal-sensors = <&tsens3 3>;
		trips {
			thermal-engine-config {
				temperature = <135000>;
				hysteresis = <5000>;
				type = "passive";
			};

			thermal-hal-config {
				temperature = <95000>;
				hysteresis = <5000>;
				type = "passive";
			};

			nsp_2_trip: nsp-2-trip {
				temperature = <95000>;
				hysteresis = <5000>;
				type = "passive";
			};

			reset-mon-cfg {
				temperature = <115000>;
				hysteresis = <0>;
				type = "hot";
			};
		};

		cooling-maps {
			cdsp_cdev {
				trip = <&nsp_2_trip>;
				cooling-device = <&cdsp_sw 0 THERMAL_NO_LIMIT>;
			};
		};
	};

	nsp-3-thermal {
		polling-delay-passive = <10>;
		thermal-sensors = <&tsens3 4>;
		trips {
			thermal-engine-config {
				temperature = <135000>;
				hysteresis = <5000>;
				type = "passive";
			};

			thermal-hal-config {
				temperature = <95000>;
				hysteresis = <5000>;
				type = "passive";
			};

			nsp_3_trip: nsp-3-trip {
				temperature = <95000>;
				hysteresis = <5000>;
				type = "passive";
			};

			reset-mon-cfg {
				temperature = <115000>;
				hysteresis = <0>;
				type = "hot";
			};
		};

		cooling-maps {
			cdsp_cdev {
				trip = <&nsp_3_trip>;
				cooling-device = <&cdsp_sw 0 THERMAL_NO_LIMIT>;
			};
		};
	};

	gpuss-0-thermal {
		polling-delay-passive = <4>;
		thermal-sensors = <&tsens3 5>;
		trips {
			thermal-engine-config {
				temperature = <135000>;
				hysteresis = <5000>;
				type = "passive";
			};

			thermal-hal-config {
				temperature = <95000>;
				hysteresis = <5000>;
				type = "passive";
			};

			gpu0_tj_cfg: tj_cfg {
				temperature = <95000>;
				hysteresis = <5000>;
				type = "passive";
			};

			reset-mon-cfg {
				temperature = <115000>;
				hysteresis = <0>;
				type = "hot";
			};
		};

		cooling-maps {
			gpu0_cdev {
				trip = <&gpu0_tj_cfg>;
				cooling-device = <&msm_gpu 0 THERMAL_NO_LIMIT>;
			};
		};
	};

	gpuss-1-thermal {
		polling-delay-passive = <4>;
		thermal-sensors = <&tsens3 6>;
		trips {
			thermal-engine-config {
				temperature = <135000>;
				hysteresis = <5000>;
				type = "passive";
			};

			thermal-hal-config {
				temperature = <95000>;
				hysteresis = <5000>;
				type = "passive";
			};

			gpu1_tj_cfg: tj_cfg {
				temperature = <95000>;
				hysteresis = <5000>;
				type = "passive";
			};

			reset-mon-cfg {
				temperature = <115000>;
				hysteresis = <0>;
				type = "hot";
			};
		};

		cooling-maps {
			gpu1_cdev {
				trip = <&gpu1_tj_cfg>;
				cooling-device = <&msm_gpu 0 THERMAL_NO_LIMIT>;
			};
		};
	};

	gpuss-2-thermal {
		polling-delay-passive = <4>;
		thermal-sensors = <&tsens3 7>;
		trips {
			thermal-engine-config {
				temperature = <135000>;
				hysteresis = <5000>;
				type = "passive";
			};

			thermal-hal-config {
				temperature = <95000>;
				hysteresis = <5000>;
				type = "passive";
			};

			gpu2_tj_cfg: tj_cfg {
				temperature = <95000>;
				hysteresis = <5000>;
				type = "passive";
			};

			reset-mon-cfg {
				temperature = <115000>;
				hysteresis = <0>;
				type = "hot";
			};
		};

		cooling-maps {
			gpu2_cdev {
				trip = <&gpu2_tj_cfg>;
				cooling-device = <&msm_gpu 0 THERMAL_NO_LIMIT>;
			};
		};
	};

	gpuss-3-thermal {
		polling-delay-passive = <4>;
		thermal-sensors = <&tsens3 8>;
		trips {
			thermal-engine-config {
				temperature = <135000>;
				hysteresis = <5000>;
				type = "passive";
			};

			thermal-hal-config {
				temperature = <95000>;
				hysteresis = <5000>;
				type = "passive";
			};

			gpu3_tj_cfg: tj_cfg {
				temperature = <95000>;
				hysteresis = <5000>;
				type = "passive";
			};

			reset-mon-cfg {
				temperature = <115000>;
				hysteresis = <0>;
				type = "hot";
			};
		};

		cooling-maps {
			gpu3_cdev {
				trip = <&gpu3_tj_cfg>;
				cooling-device = <&msm_gpu 0 THERMAL_NO_LIMIT>;
			};
		};
	};

	gpuss-4-thermal {
		polling-delay-passive = <4>;
		thermal-sensors = <&tsens3 9>;
		trips {
			thermal-engine-config {
				temperature = <135000>;
				hysteresis = <5000>;
				type = "passive";
			};

			thermal-hal-config {
				temperature = <95000>;
				hysteresis = <5000>;
				type = "passive";
			};

			gpu4_tj_cfg: tj_cfg {
				temperature = <95000>;
				hysteresis = <5000>;
				type = "passive";
			};

			reset-mon-cfg {
				temperature = <115000>;
				hysteresis = <0>;
				type = "hot";
			};
		};

		cooling-maps {
			gpu4_cdev {
				trip = <&gpu4_tj_cfg>;
				cooling-device = <&msm_gpu 0 THERMAL_NO_LIMIT>;
			};
		};
	};

	gpuss-5-thermal {
		polling-delay-passive = <4>;
		thermal-sensors = <&tsens3 10>;
		trips {
			thermal-engine-config {
				temperature = <135000>;
				hysteresis = <5000>;
				type = "passive";
			};

			thermal-hal-config {
				temperature = <95000>;
				hysteresis = <5000>;
				type = "passive";
			};

			gpu5_tj_cfg: tj_cfg {
				temperature = <95000>;
				hysteresis = <5000>;
				type = "passive";
			};

			reset-mon-cfg {
				temperature = <115000>;
				hysteresis = <0>;
				type = "hot";
			};
		};

		cooling-maps {
			gpu5_cdev {
				trip = <&gpu5_tj_cfg>;
				cooling-device = <&msm_gpu 0 THERMAL_NO_LIMIT>;
			};
		};
	};

	gpuss-6-thermal {
		polling-delay-passive = <4>;
		thermal-sensors = <&tsens3 11>;
		trips {
			thermal-engine-config {
				temperature = <135000>;
				hysteresis = <5000>;
				type = "passive";
			};

			thermal-hal-config {
				temperature = <95000>;
				hysteresis = <5000>;
				type = "passive";
			};

			gpu6_tj_cfg: tj_cfg {
				temperature = <95000>;
				hysteresis = <5000>;
				type = "passive";
			};

			reset-mon-cfg {
				temperature = <115000>;
				hysteresis = <0>;
				type = "hot";
			};
		};

		cooling-maps {
			gpu6_cdev {
				trip = <&gpu6_tj_cfg>;
				cooling-device = <&msm_gpu 0 THERMAL_NO_LIMIT>;
			};
		};
	};

	gpuss-7-thermal {
		polling-delay-passive = <4>;
		thermal-sensors = <&tsens3 12>;
		trips {
			thermal-engine-config {
				temperature = <135000>;
				hysteresis = <5000>;
				type = "passive";
			};

			thermal-hal-config {
				temperature = <95000>;
				hysteresis = <5000>;
				type = "passive";
			};

			gpu7_tj_cfg: tj_cfg {
				temperature = <95000>;
				hysteresis = <5000>;
				type = "passive";
			};

			reset-mon-cfg {
				temperature = <115000>;
				hysteresis = <0>;
				type = "hot";
			};
		};

		cooling-maps {
			gpu7_cdev {
				trip = <&gpu7_tj_cfg>;
				cooling-device = <&msm_gpu 0 THERMAL_NO_LIMIT>;
			};
		};
	};

	camera-0-thermal {
		thermal-sensors = <&tsens3 13>;
		trips {
			thermal-engine-config {
				temperature = <135000>;
				hysteresis = <5000>;
				type = "passive";
			};

			reset-mon-cfg {
				temperature = <115000>;
				hysteresis = <0>;
				type = "hot";
			};
		};
	};

	camera-1-thermal {
		thermal-sensors = <&tsens3 14>;
		trips {
			thermal-engine-config {
				temperature = <135000>;
				hysteresis = <5000>;
				type = "passive";
			};

			reset-mon-cfg {
				temperature = <115000>;
				hysteresis = <0>;
				type = "hot";
			};
		};
	};
};
